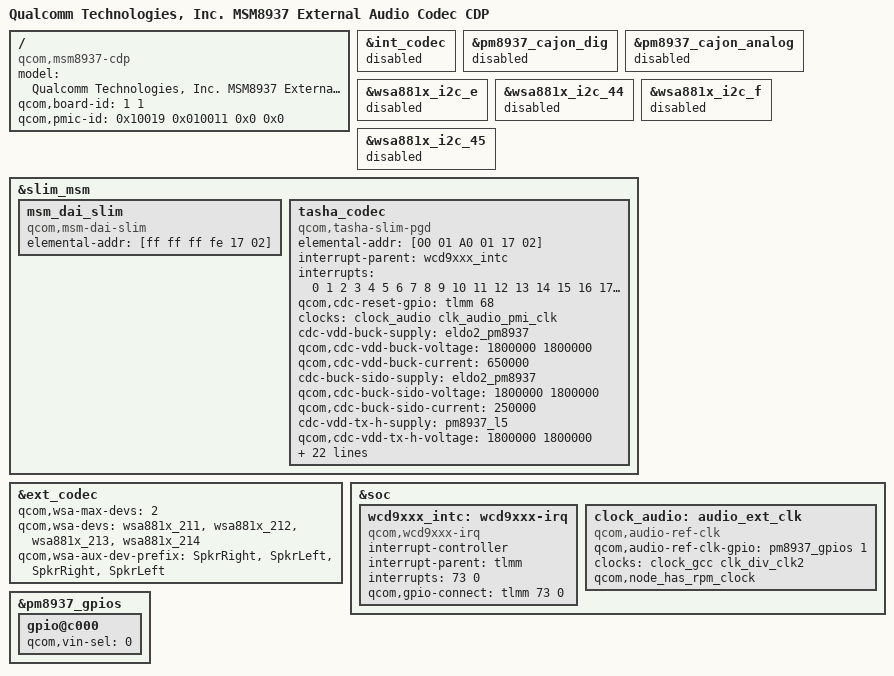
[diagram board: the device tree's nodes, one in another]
/*
 * Copyright (c) 2015, The Linux Foundation. All rights reserved.
 *
 * This program is free software; you can redistribute it and/or modify
 * it under the terms of the GNU General Public License version 2 and
 * only version 2 as published by the Free Software Foundation.
 *
 * This program is distributed in the hope that it will be useful,
 * but WITHOUT ANY WARRANTY; without even the implied warranty of
 * MERCHANTABILITY or FITNESS FOR A PARTICULAR PURPOSE.  See the
 * GNU General Public License for more details.
 */

/dts-v1/;

#include "msm8937.dtsi"
#include "msm8937-pmi8950-cdp.dtsi"
#include "msm8937-wsa881x.dtsi"

/ {
	model = "Qualcomm Technologies, Inc. MSM8937 External Audio Codec CDP";
	compatible = "qcom,msm8937-cdp", "qcom,msm8937", "qcom,cdp";
	qcom,board-id= <1 1>;
	qcom,pmic-id = <0x10019 0x010011 0x0 0x0>;
};

&int_codec {
	status = "disabled";
};

&pm8937_cajon_dig {
	status = "disabled";
};

&pm8937_cajon_analog {
	status = "disabled";
};

&wsa881x_i2c_e {
	status = "disabled";
};

&wsa881x_i2c_44 {
	status = "disabled";
};

&wsa881x_i2c_f {
	status = "disabled";
};

&wsa881x_i2c_45 {
	status = "disabled";
};

&slim_msm {
	status = "okay";
};

&ext_codec {
	qcom,wsa-max-devs = <2>;
	qcom,wsa-devs = <&wsa881x_211>, <&wsa881x_212>,
			<&wsa881x_213>, <&wsa881x_214>;
	qcom,wsa-aux-dev-prefix = "SpkrRight", "SpkrLeft",
				"SpkrRight", "SpkrLeft";
	status = "okay";
};

&soc {
	wcd9xxx_intc: wcd9xxx-irq {
		compatible = "qcom,wcd9xxx-irq";
		interrupt-controller;
		#interrupt-cells = <1>;
		interrupt-parent = <&tlmm>;
		interrupts = <73 0>;
		interrupt-names = "cdc-int";
		qcom,gpio-connect = <&tlmm 73 0>;
	};

	clock_audio: audio_ext_clk {
		compatible = "qcom,audio-ref-clk";
		qcom,audio-ref-clk-gpio = <&pm8937_gpios 1 0>;
		clock-names = "osr_clk";
		clocks = <&clock_gcc clk_div_clk2>;
		qcom,node_has_rpm_clock;
		#clock-cells = <1>;
	};
};

&pm8937_gpios {
	gpio@c000 {
		qcom,vin-sel = <0>;
	};
};

&slim_msm {
	msm_dai_slim {
		compatible = "qcom,msm-dai-slim";
		status = "okay";
		elemental-addr = [ff ff ff fe 17 02];
	};

	tasha_codec {
		compatible = "qcom,tasha-slim-pgd";
		status = "okay";
		elemental-addr = [00 01 A0 01 17 02];

		interrupt-parent = <&wcd9xxx_intc>;
		interrupts = <0 1 2 3 4 5 6 7 8 9 10 11 12 13 14 15 16
			17 18 19 20 21 22 23 24 25 26 27 28 29
			30>;

		qcom,cdc-reset-gpio = <&tlmm 68 0>;

		clock-names = "wcd_clk";
		clocks = <&clock_audio clk_audio_pmi_clk>;

		cdc-vdd-buck-supply = <&eldo2_pm8937>;
		qcom,cdc-vdd-buck-voltage = <1800000 1800000>;
		qcom,cdc-vdd-buck-current = <650000>;

		cdc-buck-sido-supply = <&eldo2_pm8937>;
		qcom,cdc-buck-sido-voltage = <1800000 1800000>;
		qcom,cdc-buck-sido-current = <250000>;

		cdc-vdd-tx-h-supply = <&pm8937_l5>;
		qcom,cdc-vdd-tx-h-voltage = <1800000 1800000>;
		qcom,cdc-vdd-tx-h-current = <25000>;

		cdc-vdd-rx-h-supply = <&pm8937_l5>;
		qcom,cdc-vdd-rx-h-voltage = <1800000 1800000>;
		qcom,cdc-vdd-rx-h-current = <25000>;

		cdc-vdd-px-supply = <&pm8937_l5>;
		qcom,cdc-vdd-px-voltage = <1800000 1800000>;
		qcom,cdc-vdd-px-current = <10000>;

		cdc-vdd-mic-bias-supply = <&pm8937_l13>;
		qcom,cdc-vdd-mic-bias-voltage = <3075000 3075000>;
		qcom,cdc-vdd-mic-bias-current = <15000>;

		qcom,cdc-static-supplies =
			"cdc-vdd-buck",
			"cdc-buck-sido",
			"cdc-vdd-tx-h",
			"cdc-vdd-rx-h",
			"cdc-vdd-px";

		qcom,cdc-micbias1-mv = <1800>;
		qcom,cdc-micbias2-mv = <1800>;
		qcom,cdc-micbias3-mv = <1800>;
		qcom,cdc-micbias4-mv = <1800>;

		qcom,cdc-mclk-clk-rate = <9600000>;
		qcom,cdc-slim-ifd = "tasha-slim-ifd";
		qcom,cdc-slim-ifd-elemental-addr = [00 00 A0 01 17 02];
		qcom,cdc-dmic-sample-rate = <4800000>;
	};
};
